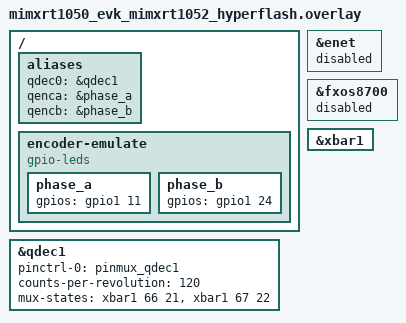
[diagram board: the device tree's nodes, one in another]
/*
 * Copyright (c) 2022 Prevas A/S
 * Copyright 2026 NXP
 *
 * SPDX-License-Identifier: Apache-2.0
 *
 * Application overlay for creating quadrature decoder device instance.
 */

/ {
	aliases {
		qdec0 = &qdec1;
		qenca = &phase_a;
		qencb = &phase_b;
		/delete-property/ magn0;
		/delete-property/ accel0;
	};

	/* Wire J22 3 <-> 5 and J22 4 <-> 6 */
	encoder-emulate {
		compatible = "gpio-leds";

		phase_a: phase_a {
			gpios = <&gpio1 11 GPIO_ACTIVE_HIGH>;
		};

		phase_b: phase_b {
			gpios = <&gpio1 24 GPIO_ACTIVE_HIGH>;
		};
	};
};

/* disable to avoid encoder phase input conflict */
&enet {
	status = "disabled";
};

/* disable to avoid encoder emulater conflict */
&fxos8700 {
	status = "disabled";
};

&xbar1 {
	status = "okay";
};

&qdec1 {
	status = "okay";
	pinctrl-0 = <&pinmux_qdec1>;
	pinctrl-names = "default";
	counts-per-revolution = <120>;
	/* mux-states cells = <output, input>:
	 *   IomuxXbarIn21 -> Enc1PhaseAInput  ->  output=66, input=21
	 *   IomuxXbarIn22 -> Enc1PhaseBInput  ->  output=67, input=22
	 */
	mux-states = <&xbar1 66 21>,
		     <&xbar1 67 22>;
};
